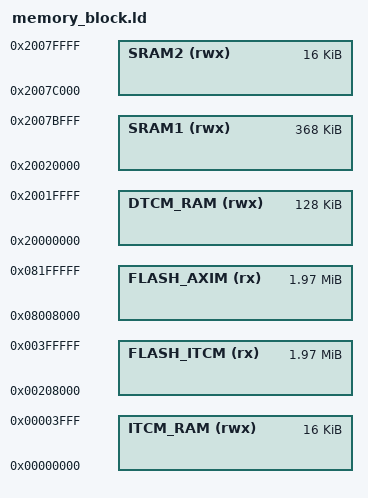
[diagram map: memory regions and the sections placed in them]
MEMORY
{
    FLASH_ITCM (rx) : ORIGIN = 0x00208000, LENGTH = 2016K
    FLASH_AXIM (rx) : ORIGIN = 0x08008000, LENGTH = 2016K

    ITCM_RAM (rwx) : ORIGIN = 0x00000000, LENGTH = 16K
    DTCM_RAM (rwx) : ORIGIN = 0x20000000, LENGTH = 128K
    SRAM1    (rwx) : ORIGIN = 0x20020000, LENGTH = 368K
    SRAM2    (rwx) : ORIGIN = 0x2007c000, LENGTH = 16K
}
